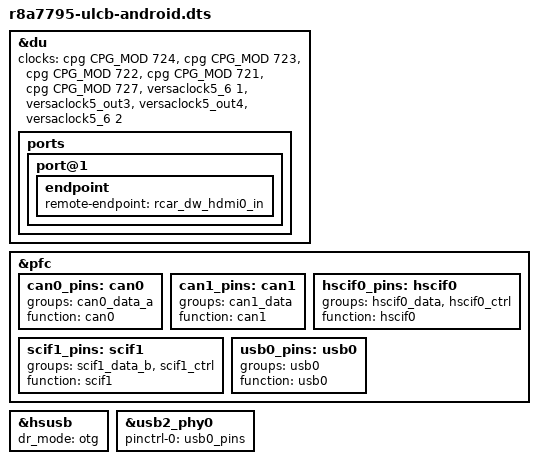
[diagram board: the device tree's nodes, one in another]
/*
 * Device Tree Source for the H3ULCB (R-Car Starter Kit Premier) board
 * Android specific extensions
 *
 * Copyright (C) 2019 GlobalLogic
 *
 * This file is licensed under the terms of the GNU General Public License
 * version 2.  This program is licensed "as is" without any warranty of any
 * kind, whether express or implied.
 */

#ifndef __H3ULCB_OVERWRITE__
#include "r8a7795-h3ulcb.dts"
#endif // __H3ULCB_OVERWRITE__
#include "android/r8a7795.dtsi"
#include "ulcb-android.dtsi"


&du {
	clocks = <&cpg CPG_MOD 724>,
		<&cpg CPG_MOD 723>,
		<&cpg CPG_MOD 722>,
		<&cpg CPG_MOD 721>,
		<&cpg CPG_MOD 727>,
		<&versaclock5_6 1>,
		<&versaclock5_out3>,
		<&versaclock5_out4>,
		<&versaclock5_6 2>;
	clock-names = "du.0", "du.1", "du.2", "du.3", "lvds.0",
		"dclkin.0", "dclkin.1", "dclkin.2", "dclkin.3";

	ports {
		port@1 {
			endpoint {
				remote-endpoint = <&rcar_dw_hdmi0_in>;
			};
		};
	};
};

&pfc {
	can0_pins: can0 {
		groups = "can0_data_a";
		function = "can0";
	};

	can1_pins: can1 {
		groups = "can1_data";
		function = "can1";
	};

	hscif0_pins: hscif0 {
		groups = "hscif0_data", "hscif0_ctrl";
		function = "hscif0";
	};

	scif1_pins: scif1 {
		groups = "scif1_data_b", "scif1_ctrl";
		function = "scif1";
	};

	usb0_pins: usb0 {
		groups = "usb0";
		function = "usb0";
	};
};

&hsusb {
	dr_mode = "otg";
	status = "okay";
};

&usb2_phy0 {
	pinctrl-0 = <&usb0_pins>;
	pinctrl-names = "default";

	status = "okay";
};

